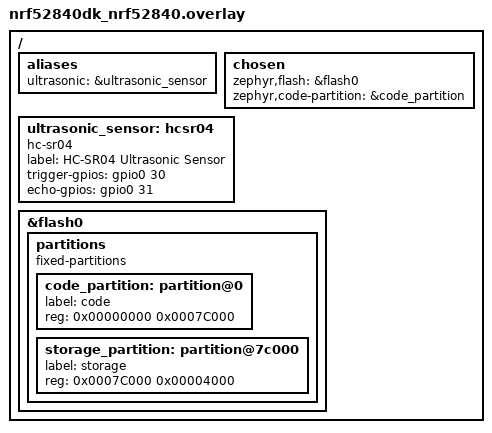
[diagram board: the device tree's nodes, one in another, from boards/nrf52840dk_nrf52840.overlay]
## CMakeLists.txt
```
cmake_minimum_required(VERSION 3.20.0)
find_package(Zephyr REQUIRED HINTS $ENV{ZEPHYR_BASE})
project(csse4011Project)

# Collect all the source files in app/prac3/src
FILE(GLOB app_sources src/*.c)

# Collect all the source files in lib. Note that
# the path given needs to be relative to the
# CMakeLists root, which is app/prac3 here,
# hence the ../../lib.c.
FILE(GLOB lib_sources ../lib/ult.c)

# Tell CMake to build with the app and lib sources
target_sources(app PRIVATE ${app_sources} ${lib_sources})

# Tell CMake where our header files are
target_include_directories(app PRIVATE ../include)
```

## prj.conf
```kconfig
CONFIG_SENSOR=y
CONFIG_GPIO=y
CONFIG_HC_SR04=y

CONFIG_SHELL=y
CONFIG_SHELL_BACKEND_SERIAL=y
CONFIG_UART_CONSOLE=y

CONFIG_BT=y
CONFIG_BT_PERIPHERAL=y
CONFIG_BT_DEVICE_NAME="ARC_NO_U1"

CONFIG_LOG=y
CONFIG_LOG_MODE_DEFERRED=y
CONFIG_LOG_DEFAULT_LEVEL=3
```

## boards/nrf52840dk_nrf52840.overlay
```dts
/ {
    aliases {
        ultrasonic = &ultrasonic_sensor;
    };

    chosen {
      zephyr,flash = &flash0;
      zephyr,code-partition = &code_partition;
    }

    ultrasonic_sensor: hcsr04 {
        compatible = "hc-sr04";
        label = "HC-SR04 Ultrasonic Sensor";
        trigger-gpios = <&gpio0 30 GPIO_ACTIVE_HIGH>;
        echo-gpios = <&gpio0 31 GPIO_ACTIVE_HIGH>;
    };

    &flash0 {
        partitions {
            compatible = "fixed-partitions";
            #address-cells = <1>;
            #size-cells = <1>;

            code_partition: partition@0 {
                label = "code";
                reg = <0x00000000 0x0007C000>;
            };

            storage_partition: partition@7c000 {
                label = "storage";
                reg = <0x0007C000 0x00004000>;
            };
        };
    };
};
```

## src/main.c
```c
#include <zephyr/kernel.h>
#include <zephyr/logging/log.h>
#include "ult.h"

LOG_MODULE_REGISTER(base_node, LOG_LEVEL_INF);

void main(void)
{
  LOG_INF("Starting ultrasonic + Bluetooth threads...");
  start_ultrasonic_thread();
  start_bluetooth_thread();
}
```
